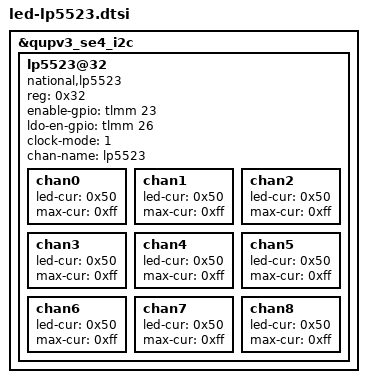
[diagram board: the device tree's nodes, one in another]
&qupv3_se4_i2c {
	status = "ok";
	lp5523@32 {
		compatible = "national,lp5523";
		reg = <0x32>;
		enable-gpio = <&tlmm 23 0x00>;
		ldo-en-gpio = <&tlmm 26 0x00>;
		clock-mode = /bits/ 8 <1>;
		chan-name = "lp5523";

		chan0 {
			led-cur = /bits/ 8 <0x50>;
			max-cur = /bits/ 8 <0xff>;
		};

		chan1 {
			led-cur = /bits/ 8 <0x50>;
			max-cur = /bits/ 8 <0xff>;
		};

		chan2 {
			led-cur = /bits/ 8 <0x50>;
			max-cur = /bits/ 8 <0xff>;
		};

		chan3 {
			led-cur = /bits/ 8 <0x50>;
			max-cur = /bits/ 8 <0xff>;
		};

		chan4 {
			led-cur = /bits/ 8 <0x50>;
			max-cur = /bits/ 8 <0xff>;
		};

		chan5 {
			led-cur = /bits/ 8 <0x50>;
			max-cur = /bits/ 8 <0xff>;
		};

		chan6 {
			led-cur = /bits/ 8 <0x50>;
			max-cur = /bits/ 8 <0xff>;
		};

		chan7 {
			led-cur = /bits/ 8 <0x50>;
			max-cur = /bits/ 8 <0xff>;
		};

		chan8 {
			led-cur = /bits/ 8 <0x50>;
			max-cur = /bits/ 8 <0xff>;
		};
	};
};
